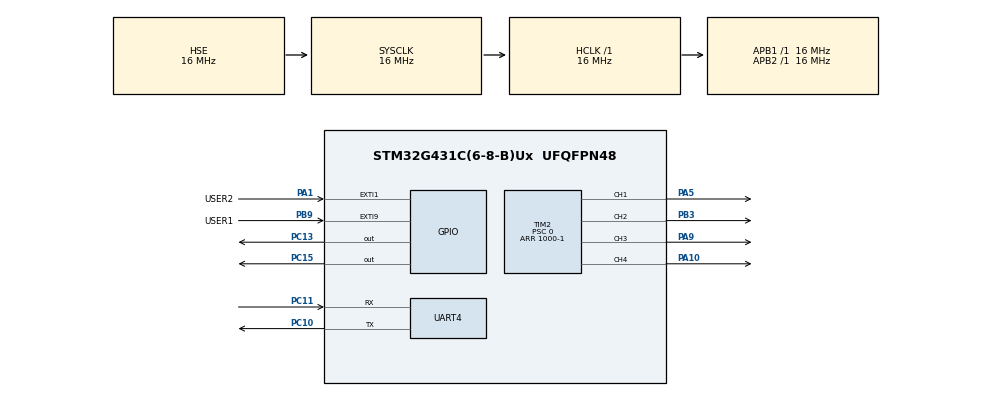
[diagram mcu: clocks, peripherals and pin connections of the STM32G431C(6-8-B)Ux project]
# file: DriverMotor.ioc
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FREERTOS.Tasks01=defaultTask,0,128,StartDefaultTask,Default,NULL,Dynamic,NULL,NULL
FREERTOS.configUSE_NEWLIB_REENTRANT=1
Mcu.Family=STM32G4
Mcu.Name=STM32G431C(6-8-B)Ux
Mcu.Package=UFQFPN48
NVIC.EXTI1_IRQn=true\:5\:0\:true\:false\:true\:true\:true\:true\:true
NVIC.EXTI9_5_IRQn=true\:5\:0\:true\:false\:true\:true\:true\:true\:true
NVIC.PriorityGroup=NVIC_PRIORITYGROUP_4
NVIC.RCC_IRQn=true\:5\:0\:false\:false\:true\:true\:true\:false\:true
NVIC.TIM2_IRQn=true\:5\:0\:false\:false\:true\:true\:true\:true\:true
NVIC.TIM6_DAC_IRQn=true\:15\:0\:false\:false\:true\:false\:false\:true\:true
NVIC.TimeBase=TIM6_DAC_IRQn
NVIC.TimeBaseIP=TIM6
PA1.GPIO_Label=USER2
PA1.GPIO_ModeDefaultEXTI=GPIO_MODE_IT_FALLING
PA1.GPIO_PuPd=GPIO_PULLUP
PA1.Signal=GPXTI1
PA10.Signal=S_TIM2_CH4
PA5.Signal=S_TIM2_CH1
PA9.Signal=S_TIM2_CH3
PB3.Signal=S_TIM2_CH2
PB9.GPIO_Label=USER1
PB9.GPIO_ModeDefaultEXTI=GPIO_MODE_IT_FALLING
PB9.GPIO_PuPd=GPIO_PULLUP
PB9.Signal=GPXTI9
PC10.Mode=Asynchronous
PC10.Signal=UART4_TX
PC11.Mode=Asynchronous
PC11.Signal=UART4_RX
PC13.Signal=GPIO_Output
PC15-OSC32_OUT.Signal=GPIO_Output
PF0-OSC_IN.Mode=HSE-External-Oscillator
PF0-OSC_IN.Signal=RCC_OSC_IN
PF1-OSC_OUT.Mode=HSE-External-Oscillator
PF1-OSC_OUT.Signal=RCC_OSC_OUT
ProjectManager.HeapSize=0x200
ProjectManager.StackSize=0x400
ProjectManager.TargetToolchain=STM32CubeIDE
RCC.AHBFreq_Value=16000000
RCC.APB1Freq_Value=16000000
RCC.APB1TimFreq_Value=16000000
RCC.APB2Freq_Value=16000000
RCC.APB2TimFreq_Value=16000000
RCC.CortexFreq_Value=16000000
RCC.EXTERNAL_CLOCK_VALUE=12288000
RCC.HCLKFreq_Value=16000000
RCC.HSE_VALUE=16000000
RCC.HSI48_VALUE=48000000
RCC.HSI_VALUE=16000000
RCC.LSE_VALUE=32768
RCC.SYSCLKFreq_VALUE=16000000
RCC.SYSCLKSource=RCC_SYSCLKSOURCE_HSE
RCC.USBFreq_Value=64000000
RCC.VCOOutputFreq_Value=128000000
SH.S_TIM2_CH1.0=TIM2_CH1,PWM Generation1 CH1
SH.S_TIM2_CH2.0=TIM2_CH2,PWM Generation2 CH2
SH.S_TIM2_CH3.0=TIM2_CH3,PWM Generation3 CH3
SH.S_TIM2_CH4.0=TIM2_CH4,PWM Generation4 CH4
TIM2.Channel-PWM\ Generation1\ CH1=TIM_CHANNEL_1
TIM2.Channel-PWM\ Generation2\ CH2=TIM_CHANNEL_2
TIM2.Channel-PWM\ Generation3\ CH3=TIM_CHANNEL_3
TIM2.Channel-PWM\ Generation4\ CH4=TIM_CHANNEL_4
TIM2.OCPolarity_1=TIM_OCPOLARITY_HIGH
TIM2.OCPolarity_2=TIM_OCPOLARITY_HIGH
TIM2.OCPolarity_3=TIM_OCPOLARITY_HIGH
TIM2.OCPolarity_4=TIM_OCPOLARITY_HIGH
TIM2.PeriodNoDither=1000-1
TIM2.Prescaler=0
VP_FREERTOS_VS_CMSIS_V1.Mode=CMSIS_V1
VP_SYS_VS_DBSignals.Mode=DisableDeadBatterySignals
VP_SYS_VS_tim6.Mode=TIM6
VP_TIM2_VS_ClockSourceINT.Mode=Internal
board=custom

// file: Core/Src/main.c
/* USER CODE BEGIN Header */
/**
  ******************************************************************************
  * @file           : main.c
  * @brief          : Main program body
  ******************************************************************************
  * @attention
  *
  * Copyright (c) 2025 STMicroelectronics.
  * All rights reserved.
  *
  * This software is licensed under terms that can be found in the LICENSE file
  * in the root directory of this software component.
  * If no LICENSE file comes with this software, it is provided AS-IS.
  *
  ******************************************************************************
  */
/* USER CODE END Header */
#include "main.h"
#include "cmsis_os.h"
#include "tim.h"
#include "usart.h"
#include "gpio.h"

/* USER CODE BEGIN Includes */
#include "motor.h"
#include <stdio.h>
/* USER CODE END Includes */

/* USER CODE BEGIN PV */
SemaphoreHandle_t xMotorSem;
/* USER CODE END PV */

void SystemClock_Config(void);
void MX_FREERTOS_Init(void);

/* USER CODE BEGIN 0 */

int __io_putchar(int chr)
{
	HAL_UART_Transmit(&huart4, (uint8_t*)&chr,1,HAL_MAX_DELAY);
	return chr;
}

/* USER CODE END 0 */

int main(void)
{

  /* MCU Configuration--------------------------------------------------------*/

  /* Reset of all peripherals, Initializes the Flash interface and the Systick. */
  HAL_Init();

  /* Configure the system clock */
  SystemClock_Config();

  /* Initialize all configured peripherals */
  MX_GPIO_Init();
  MX_TIM2_Init();
  MX_UART4_Init();
  /* USER CODE BEGIN 2 */

  Init_motors();
  CreateTaskMotors();

  HAL_Delay(500);

  printf("\r\n==== DriverMoteur ====\r\n");

  vTaskStartScheduler();
  /* USER CODE END 2 */

  /* Call init function for freertos objects (in cmsis_os2.c) */
  MX_FREERTOS_Init();

  /* Start scheduler */
  osKernelStart();

  /* We should never get here as control is now taken by the scheduler */

  /* Infinite loop */
  while (1)
  {

    /* USER CODE BEGIN 3 */

//	  HAL_GPIO_TogglePin(GPIOC, GPIO_PIN_15);
//	  __HAL_TIM_SET_COMPARE(&htim2, TIM_CHANNEL_3, 0);
//	  __HAL_TIM_SET_COMPARE(&htim2, TIM_CHANNEL_4, 400);
//
//
//	  HAL_Delay(1000);
//
//
//	  __HAL_TIM_SET_COMPARE(&htim2, TIM_CHANNEL_4, 0);
//	  __HAL_TIM_SET_COMPARE(&htim2, TIM_CHANNEL_3, 400);
//
//	  HAL_Delay(1000);
//
//	  __HAL_TIM_SET_COMPARE(&htim2, TIM_CHANNEL_3, 0);
//	  HAL_GPIO_TogglePin(GPIOC, GPIO_PIN_15);
//	  HAL_GPIO_TogglePin(GPIOC, GPIO_PIN_13);
//
//
//	  __HAL_TIM_SET_COMPARE(&htim2, TIM_CHANNEL_1, 0);
//	  __HAL_TIM_SET_COMPARE(&htim2, TIM_CHANNEL_2, 400);
//
//
//	  HAL_Delay(1000);
//
//
//	  __HAL_TIM_SET_COMPARE(&htim2, TIM_CHANNEL_2, 0);
//	  __HAL_TIM_SET_COMPARE(&htim2, TIM_CHANNEL_1, 400);
//
//	  HAL_Delay(1000);
//
//	  HAL_GPIO_TogglePin(GPIOC, GPIO_PIN_13);
//	  __HAL_TIM_SET_COMPARE(&htim2, TIM_CHANNEL_1, 0);

  }
  /* USER CODE END 3 */
}

void SystemClock_Config(void)
{
  RCC_OscInitTypeDef RCC_OscInitStruct = {0};
  RCC_ClkInitTypeDef RCC_ClkInitStruct = {0};

  /** Configure the main internal regulator output voltage
  */
  HAL_PWREx_ControlVoltageScaling(PWR_REGULATOR_VOLTAGE_SCALE1);

  /** Initializes the RCC Oscillators according to the specified parameters
  * in the RCC_OscInitTypeDef structure.
  */
  RCC_OscInitStruct.OscillatorType = RCC_OSCILLATORTYPE_HSE;
  RCC_OscInitStruct.HSEState = RCC_HSE_ON;
  RCC_OscInitStruct.PLL.PLLState = RCC_PLL_NONE;
  if (HAL_RCC_OscConfig(&RCC_OscInitStruct) != HAL_OK)
  {
    Error_Handler();
  }

  /** Initializes the CPU, AHB and APB buses clocks
  */
  RCC_ClkInitStruct.ClockType = RCC_CLOCKTYPE_HCLK|RCC_CLOCKTYPE_SYSCLK
                              |RCC_CLOCKTYPE_PCLK1|RCC_CLOCKTYPE_PCLK2;
  RCC_ClkInitStruct.SYSCLKSource = RCC_SYSCLKSOURCE_HSE;
  RCC_ClkInitStruct.AHBCLKDivider = RCC_SYSCLK_DIV1;
  RCC_ClkInitStruct.APB1CLKDivider = RCC_HCLK_DIV1;
  RCC_ClkInitStruct.APB2CLKDivider = RCC_HCLK_DIV1;

  if (HAL_RCC_ClockConfig(&RCC_ClkInitStruct, FLASH_LATENCY_0) != HAL_OK)
  {
    Error_Handler();
  }
}

void HAL_TIM_PeriodElapsedCallback(TIM_HandleTypeDef *htim)
{
  if (htim->Instance == TIM6)
  {
    HAL_IncTick();
  }
}

void Error_Handler(void)
{
  __disable_irq();
  while (1)
  {
  }
}
